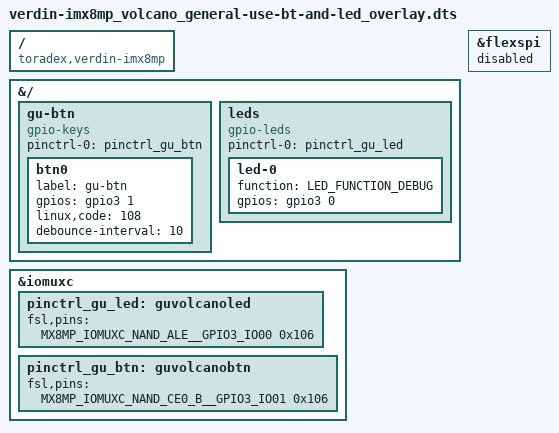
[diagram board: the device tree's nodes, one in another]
// SPDX-License-Identifier: GPL-2.0-or-later OR MIT
/*
 * Copyright 2023 Toradex
 */

// General use button and led on Embtech Volcano base board.

/dts-v1/;
/plugin/;

#include <dt-bindings/gpio/gpio.h>
#include <dt-bindings/interrupt-controller/irq.h>
#include <dt-bindings/leds/common.h>
#include <dt-bindings/../../arch/arm64/boot/dts/freescale/imx8mp-pinfunc.h>

/ {
	compatible = "toradex,verdin-imx8mp";
};

&{/} {
	gu-btn {
		compatible = "gpio-keys";
		pinctrl-names = "default";
		pinctrl-0 = <&pinctrl_gu_btn>;

		/* SODIMM 54 - General use button */
		btn0 {
			label = "gu-btn";
			gpios = <&gpio3 1 GPIO_ACTIVE_HIGH>;
			linux,code = <108>;
			debounce-interval = <10>;
		};
	};

	leds {
		compatible = "gpio-leds";
		pinctrl-names = "default";
		pinctrl-0 = <&pinctrl_gu_led>;

		/* SODIMM 52 - General use LED */
		led-0 {
				function = LED_FUNCTION_DEBUG;
				gpios = <&gpio3 0 GPIO_ACTIVE_HIGH>;
		};
	};
};

&flexspi {
	status = "disabled";
};

&iomuxc {
        pinctrl_gu_led: guvolcanoled {
                fsl,pins = <
                        MX8MP_IOMUXC_NAND_ALE__GPIO3_IO00       0x106   /* SODIMM 52 */
                >;
        };

        pinctrl_gu_btn: guvolcanobtn {
                fsl,pins = <
                        MX8MP_IOMUXC_NAND_CE0_B__GPIO3_IO01     0x106   /* SODIMM 54 */
                >;
        };
};
